# APM32F411 register map
Vendor: Geehy; File version: 2024.11.05
CPU: CM4 r1p0, little endian, 3 interrupt priority bits
Registers are 32-bit, read-write, reset 0x0 unless marked. A register's access mark holds for its fields unless they carry their own. Offsets are from the block's base; [hi:lo] are bit positions; 'fields as' and 'values as' point back to an identical list.

## USART1 — Universal synchronous asynchronous receiver transmitter
Base 0x40011000
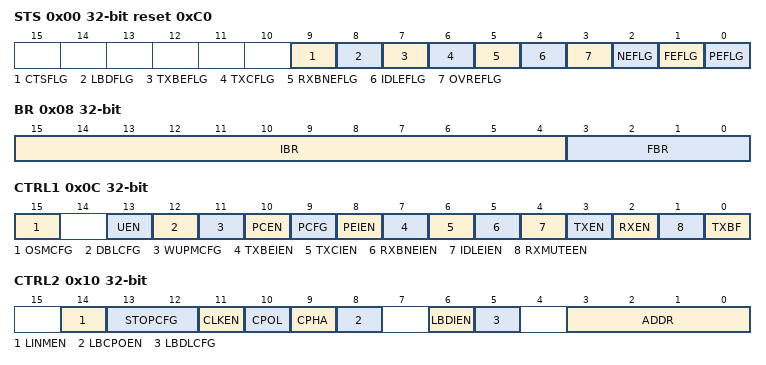
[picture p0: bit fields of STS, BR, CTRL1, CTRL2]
0x00 STS access per field reset 0xC0 — Status register
  [9] CTSFLG rw — Set by hardware when CTS flow control is enabled (see CTSEN bitfield from CTRL3 register) and the nCTS pin toggles. Cleared by writing 0 to this bit.
    0=NO_CHANGE (No change in CTS line); 1=CTS_CHANGED (CTS line changed)
  [8] LBDFLG rw — Set by hardware when a LIN break is detected. Cleared by writing 0 to this bit.
    0=NO_LIN_BREAK (No LIN break detected); 1=LIN_BREAK_DETECTED
  [7] TXBEFLG ro — Set by hardware when the shift register has loaded data from DATA register. Cleared by writing to DATA register.
    0=BUFFER_NOT_EMPTY (TX buffer not empty); 1=BUFFER_EMPTY (TX buffer empty)
  [6] TXCFLG rw — Set by hardware after the last frame is transmitted and TXBEFLG=1 (which means the Transmit Buffer is empty). Cleared by reading USART_STS, then writing 0 to this bit, or by writing DATA.
    0=NOT_COMPLETE (Transmission not complete); 1=COMPLETE (Last frame transmission complete)
  [5] RXBNEFLG rw — Set by hardware when data is transferred from shift register to DATA. Cleared by reading DATA or by writing 0 to this bit.
    0=BUFFER_EMPTY (Receive buffer empty); 1=BUFFER_NOT_EMPTY (Receive buffer contains data)
  [4] IDLEFLG ro — Set by hardware when an idle bus is detected. Cleared by reading USART_STS and then reading USART_DATA.
    0=NO_IDLE_LINE (No idle line detected); 1=IDLE_DETECTED (Idle line detected)
  [3] OVREFLG ro — Set by hardware when new data arrives while RXBNEFLG=1 (which means the receive data buffer is full). Cleared by reading USART_STS and then reading USART_DATA.
    0=NO_OVERRUN (No overrun error); 1=OVERRUN_ERROR (Overrun error occurred)
  [2] NEFLG ro — Set by hardware when noise is detected during reception. Cleared by reading USART_STS and then reading USART_DATA.
    0=NO_NOISE_ERROR; 1=NOISE_ERROR (Noise error detected)
  [1] FEFLG ro — Set by hardware if stop bit is missing, too much noise, or on break symbol. Cleared by reading USART_STS and then reading USART_DATA.
    0=NO_FRAME_ERROR; 1=FRAME_ERROR (Frame error or break detected)
  [0] PEFLG ro — Set by hardware in receive mode when a parity error is detected. Clear by software, after setting of RXBNEFLG, first read USART_STS and then read USART_DATA.
    0=NO_PARITY_ERROR; 1=PARITY_ERROR (Parity check error occurred)
0x04 DATA
  [8:0] DATA — Transmit or receive data value. Reading this register returns the received data. Writing to this register sends data. If parity is enabled and using 9 data bits, bit 8 is the parity bit. If parity is enabled and using 8 data bits, bit 7 is the parity bit.
0x08 BR — Baud rate register
  [15:4] IBR — mantissa of USARTDIV
  [3:0] FBR — fraction of USARTDIV
0x0C CTRL1 — Control Register 1
  [15] OSMCFG — Configures the oversampling mode for the USART.
    0=16X (16x oversampling); 1=8X (8x oversampling)
  [13] UEN — Enables or disables the USART module.
    0=DISABLED (USART disabled); 1=ENABLED (USART enabled)
  [12] DBLCFG — Configures the word length: 8 or 9 bits.
    0=BITS_8 (8 data bits); 1=BITS_9 (9 data bits)
  [11] WUPMCFG — Selects the wakeup method when the USART is in mute mode.
    0=ADDRESS_MARK (Address mark wakeup); 1=IDLE_LINE (Idle line wakeup)
  [10] PCEN — Enables or disables parity control.
    0=DISABLED (Parity control disabled); 1=ENABLED (Parity control enabled)
  [9] PCFG — Configures the parity mode: even or odd.
    0=EVEN (Even parity); 1=ODD (Odd parity)
  [8] PEIEN — Enables or disables the interrupt on a parity error detection.
    0=DISABLED (Interrupt disabled); 1=ENABLED (Interrupt enabled)
  [7] TXBEIEN — Enables or disables the interrupt when the TX buffer is empty.
    values as PEIEN
  [6] TXCIEN — Enables or disables the interrupt when a transmission is complete.
    values as PEIEN
  [5] RXBNEIEN — Enables or disables the interrupt when the RX buffer is not empty.
    values as PEIEN
  [4] IDLEIEN — Enables or disables the interrupt when the IDLE line is detected.
    0=DISABLED (IDLE interrupt disabled); 1=ENABLED (IDLE interrupt enabled)
  [3] TXEN — Enables or disables the USART transmitter. The transmitter is used to send data.
    0=DISABLED (Transmitter disabled); 1=ENABLED (Transmitter enabled)
  [2] RXEN — Enables or disables the USART receiver. The receiver can be disabled during low-power sleep modes.
    0=DISABLED (Receiver disabled); 1=ENABLED (Receiver enabled)
  [1] RXMUTEEN — Enables or disables the USART receiver in mute mode.
    0=DISABLED (Mute mode disabled); 1=ENABLED (Mute mode enabled)
  [0] TXBF — This bit can be set by software and cleared to 0 by hardware when the stop bit of the break frame is transmitted.
    0=NOT_TRANSMIT (Break frame not transmitted); 1=TRANSMIT (Break frame will be transmitted)
0x10 CTRL2 — Control Register 2
  [14] LINMEN — Enables or disables the LIN mode functionality.
    0=DISABLED (LIN mode disabled); 1=ENABLED (LIN mode enabled)
  [13:12] STOPCFG — Configures the number of stop bits for data transmission. This bit does not exist on UART4 or UART5.
    0=1_STOP (1 stop bit); 1=0_5_STOP (0.5 stop bit); 2=2_STOP (2 stop bits); 3=1_5_STOP (1.5 stop bits)
  [11] CLKEN — Enables or disables the clock output on the CK pin in synchronous mode. This bit does not exist on UART4 or UART5.
  [10] CPOL — Sets the state of the CK pin when the USART is idle in synchronous mode. This bit does not exist on UART4 or UART5.
    0=LOW (Idle state is low); 1=HIGH (Idle state is high)
  [9] CPHA — Indicates on which clock edge data sampling is conducted in synchronous mode. This bit does not exist on UART4 or UART5.
    0=FIRST_EDGE (Data sampling on the first clock edge); 1=SECOND_EDGE (Data sampling on the second clock edge)
  [8] LBCPOEN — Enables or disables the output of the clock pulse for the last data bit in synchronous mode. This bit does not exist on UART4 or UART5.
  [6] LBDIEN — Enables or disables interrupts on LIN break detection. Generates an interrupt when the LBDFLG bit is set.
    values as CTRL1.PEIEN
  [5] LBDLCFG — Configures the length of LIN break detection: 10 or 11 bits.
    0=10_BITS (10 bits for LIN break detection); 1=11_BITS (11 bits for LIN break detection)
  [3:0] ADDR — USART device node address. This bit is valid only in the mute mode of multiprocessor communication, and decides to enter the mute mode or wake up depending on whether the detected address tags are consistent.
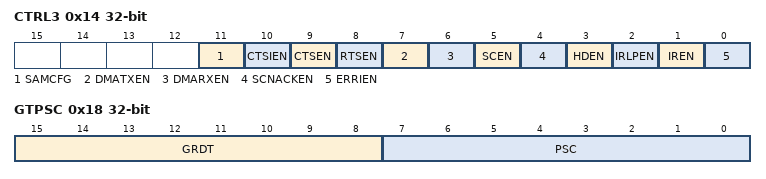
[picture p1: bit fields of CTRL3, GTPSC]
0x14 CTRL3 — Control register 3
  [11] SAMCFG — Sample Method Configure. This bit can be set only when USART is not enabled.
    0=THREE_SAMPLE (Sampling for three times); 1=SINGLE_SAMPLE (Single sampling; flag of noise detection disabled)
  [10] CTSIEN — CTS Interrupt Enable: An interrupt will be generated when CTSFLG is set. (This bit does not exist on UART4 or UART5).
    0=DISABLED (CTS interrupt disabled); 1=ENABLED (CTS interrupt enabled)
  [9] CTSEN — CTS Hardware Flow Control Function Enable. CTS: 'Clear To Send', which is an input signal. Only when CTS input signal is low, the data can be transmitted; otherwise, the data cannot be transmitted. If CTS signal is pulled high during data transmission, the data transmission will be stopped after completion. If write operation is performed for the data register when CTS is high, the data will not be transmitted until CTS is valid. (This bit does not exist on UART4 or UART5).
    0=DISABLED (CTS flow control disabled); 1=ENABLED (CTS flow control enabled)
  [8] RTSEN — RTS Hardware Flow Control Function Enable. RTS: 'Request To Send', which is an output signal indicating readiness to receive. This request to receive data is only made when there is space in the receive buffer: when data can be received, the RTS output is pulled to low. (This bit does not exist on UART4 or UART5).
    0=DISABLED (RTS flow control disabled); 1=ENABLED (RTS flow control enabled)
  [7] DMATXEN — DMA Transmit Enable (This bit does not exist on UART4 or UART5).
    0=DISABLED (DMA transmitter disabled); 1=ENABLED (DMA transmitter enabled)
  [6] DMARXEN — DMA Receive Enable (This bit does not exist on UART4 or UART5).
    0=DISABLED (DMA receiver disabled); 1=ENABLED (DMA receiver enabled)
  [5] SCEN — SCEN bit of USART_CTRL3 register decides whether to enter the smart card mode (This bit does not exist on UART4 or UART5).
    0=DISABLED (Smartcard mode disabled); 1=ENABLED (Smartcard mode enabled)
  [4] SCNACKEN — NACK Transmit Enable During Parity Error in Smartcard Function (This bit does not exist on UART4 or UART5).
    0=NO_NACK (Do not transmit NACK on parity error); 1=NACK_ON_ERROR (Transmit NACK on parity error)
  [3] HDEN — HDEN bit of USART_CTRL3 register determines whether to enter the single-line half-duplex mode.
    0=DISABLED (Half-duplex mode disabled); 1=ENABLED (Half-duplex mode enabled)
  [2] IRLPEN — IrDA Low-power Mode Enable
    0=NORMAL_MODE (Normal IrDA mode); 1=LOW_POWER_MODE (Low-power IrDA mode)
  [1] IREN — IrDA Function Enable
    0=DISABLED (IrDA disabled); 1=ENABLED (IrDA enabled)
  [0] ERRIEN — Error interrupt Enable
    0=DISABLED (Error interrupt disabled); 1=ENABLED (Error interrupt enabled. When DMARXEN is set and one among FEFLG, OVREFLG or NEFLG is set, an interrupt will be generated.)
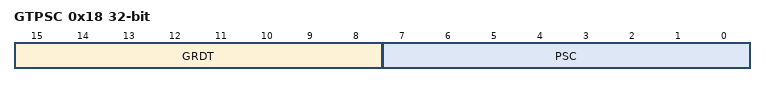
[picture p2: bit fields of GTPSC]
0x18 GTPSC — Guard time and prescaler register. Cannot be used for UART4 and UART5.
  [15:8] GRDT — Sets the guard time (in baud clock cycles). In Smart Card mode, this delays TXCFLG until the guard time finishes. 0 means no additional guard time; up to 255 for the maximum delay.
  [7:0] PSC — Divides the system clock to provide the clock for IR or Smart Card mode. In IR low-power mode, PSC[7:0] can be 1..255 (0 is reserved). In IR normal mode, PSC must be 1. In Smart Card mode, PSC[4:0] is significant (0 is reserved; a nonzero value corresponds to 2x(PSC[4:0]) prescaler, e.g. 1 => 2, 2 => 4, etc.).

## USART2 — Universal synchronous asynchronous receiver transmitter
Base 0x40004400
Same registers: USART3 0x40004800, USART6 0x40011400
Registers as USART1; these are added or differ:
0x04 DATA
  [8:0] DATA — Transmit or receive data value. - Reading this register returns the received data. - Writing to this register sends data. If parity is enabled and using 9 data bits, bit 8 is the parity bit. If parity is enabled and using 8 data bits, bit 7 is the parity bit.
0x18 GTPSC — Guard time and prescaler register. Cannot be used for UART4 and UART5.
  [15:8] GRDT — Sets the guard time (in baud clock cycles). In Smart Card mode, this delays TXCFLG until the guard time finishes. 0 means no additional guard time; up to 255 for the maximum delay.
  [7:0] PSC — Divides the system clock to provide the clock for IR or Smart Card mode. - In IR low-power mode, PSC[7:0] can be 1..255 (0 is reserved). - In IR normal mode, PSC must be 1. - In Smart Card mode, PSC[4:0] is significant (0 is reserved; a nonzero value corresponds to 2x(PSC[4:0]) prescaler, e.g. 1 => 2, 2 => 4, etc.).
